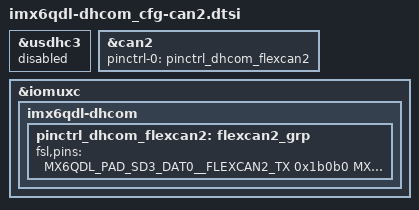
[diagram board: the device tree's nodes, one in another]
/*
 * Copyright 2017 DH electronics GmbH
 *
 * The code contained herein is licensed under the GNU General Public
 * License. You may obtain a copy of the GNU General Public License
 * Version 2 or later at the following locations:
 *
 * http://www.opensource.org/licenses/gpl-license.html
 * http://www.gnu.org/copyleft/gpl.html
 */

&usdhc3 {									// Mirco SD card (onModule)
	status = "disabled";							// CAN uses pins of SDIO
};

&can2 {										// CAN 2
	pinctrl-names = "default";
	pinctrl-0 = <&pinctrl_dhcom_flexcan2>;
	status = "okay";
};

&iomuxc {
	imx6qdl-dhcom {
		pinctrl_dhcom_flexcan2: flexcan2_grp {
			fsl,pins = <
				MX6QDL_PAD_SD3_DAT0__FLEXCAN2_TX    0x1b0b0
				MX6QDL_PAD_SD3_DAT1__FLEXCAN2_RX    0x1b0b0
			>;
		};
	};
};
